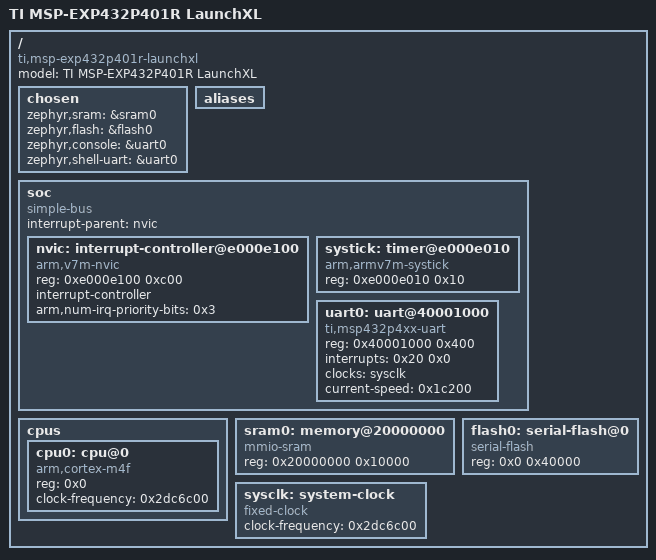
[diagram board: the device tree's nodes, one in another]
/dts-v1/;

/* node '/' defined in zephyr/dts/common/skeleton.dtsi:9 */
/ {
	#address-cells = < 0x1 >;                   /* in zephyr/dts/common/skeleton.dtsi:10 */
	#size-cells = < 0x1 >;                      /* in zephyr/dts/common/skeleton.dtsi:11 */
	model = "TI MSP-EXP432P401R LaunchXL";      /* in zephyr/boards/ti/msp_exp432p401r_launchxl/msp_exp432p401r_launchxl.dts:9 */
	compatible = "ti,msp-exp432p401r-launchxl",
	             "ti,msp432p401r",
	             "ti,msp432p4xx";               /* in zephyr/boards/ti/msp_exp432p401r_launchxl/msp_exp432p401r_launchxl.dts:10 */

	/* node '/chosen' defined in zephyr/dts/common/skeleton.dtsi:13 */
	chosen {
		zephyr,sram = &sram0;       /* in zephyr/boards/ti/msp_exp432p401r_launchxl/msp_exp432p401r_launchxl.dts:14 */
		zephyr,flash = &flash0;     /* in zephyr/boards/ti/msp_exp432p401r_launchxl/msp_exp432p401r_launchxl.dts:15 */
		zephyr,console = &uart0;    /* in zephyr/boards/ti/msp_exp432p401r_launchxl/msp_exp432p401r_launchxl.dts:16 */
		zephyr,shell-uart = &uart0; /* in zephyr/boards/ti/msp_exp432p401r_launchxl/msp_exp432p401r_launchxl.dts:17 */
	};

	/* node '/aliases' defined in zephyr/dts/common/skeleton.dtsi:15 */
	aliases {
	};

	/* node '/soc' defined in zephyr/dts/arm/armv7-m.dtsi:6 */
	soc {
		#address-cells = < 0x1 >;     /* in zephyr/dts/arm/armv7-m.dtsi:7 */
		#size-cells = < 0x1 >;        /* in zephyr/dts/arm/armv7-m.dtsi:8 */
		compatible = "simple-bus";    /* in zephyr/dts/arm/armv7-m.dtsi:9 */
		interrupt-parent = < &nvic >; /* in zephyr/dts/arm/armv7-m.dtsi:10 */
		ranges;                       /* in zephyr/dts/arm/armv7-m.dtsi:11 */

		/* node '/soc/interrupt-controller@e000e100' defined in zephyr/dts/arm/armv7-m.dtsi:13 */
		nvic: interrupt-controller@e000e100 {
			#address-cells = < 0x1 >;            /* in zephyr/dts/arm/armv7-m.dtsi:14 */
			compatible = "arm,v7m-nvic";         /* in zephyr/dts/arm/armv7-m.dtsi:15 */
			reg = < 0xe000e100 0xc00 >;          /* in zephyr/dts/arm/armv7-m.dtsi:16 */
			interrupt-controller;                /* in zephyr/dts/arm/armv7-m.dtsi:17 */
			#interrupt-cells = < 0x2 >;          /* in zephyr/dts/arm/armv7-m.dtsi:18 */
			arm,num-irq-priority-bits = < 0x3 >; /* in zephyr/dts/arm/ti/msp432p4xx.dtsi:42 */
			phandle = < 0x1 >;                   /* in zephyr/dts/arm/armv7-m.dtsi:10 */
		};

		/* node '/soc/timer@e000e010' defined in zephyr/dts/arm/armv7-m.dtsi:21 */
		systick: timer@e000e010 {
			compatible = "arm,armv7m-systick"; /* in zephyr/dts/arm/armv7-m.dtsi:22 */
			reg = < 0xe000e010 0x10 >;         /* in zephyr/dts/arm/armv7-m.dtsi:23 */
		};

		/* node '/soc/uart@40001000' defined in zephyr/dts/arm/ti/msp432p4xx.dtsi:31 */
		uart0: uart@40001000 {
			compatible = "ti,msp432p4xx-uart"; /* in zephyr/dts/arm/ti/msp432p4xx.dtsi:32 */
			reg = < 0x40001000 0x400 >;        /* in zephyr/dts/arm/ti/msp432p4xx.dtsi:33 */
			interrupts = < 0x20 0x0 >;         /* in zephyr/dts/arm/ti/msp432p4xx.dtsi:34 */
			clocks = < &sysclk >;              /* in zephyr/dts/arm/ti/msp432p4xx.dtsi:35 */
			status = "okay";                   /* in zephyr/boards/ti/msp_exp432p401r_launchxl/msp_exp432p401r_launchxl.dts:26 */
			current-speed = < 0x1c200 >;       /* in zephyr/boards/ti/msp_exp432p401r_launchxl/msp_exp432p401r_launchxl.dts:27 */
		};
	};

	/* node '/cpus' defined in zephyr/dts/arm/ti/msp432p4xx.dtsi:6 */
	cpus {
		#address-cells = < 0x1 >; /* in zephyr/dts/arm/ti/msp432p4xx.dtsi:7 */
		#size-cells = < 0x0 >;    /* in zephyr/dts/arm/ti/msp432p4xx.dtsi:8 */

		/* node '/cpus/cpu@0' defined in zephyr/dts/arm/ti/msp432p4xx.dtsi:10 */
		cpu0: cpu@0 {
			compatible = "arm,cortex-m4f";   /* in zephyr/dts/arm/ti/msp432p4xx.dtsi:11 */
			reg = < 0x0 >;                   /* in zephyr/dts/arm/ti/msp432p4xx.dtsi:12 */
			clock-frequency = < 0x2dc6c00 >; /* in zephyr/boards/ti/msp_exp432p401r_launchxl/msp_exp432p401r_launchxl.dts:22 */
		};
	};

	/* node '/memory@20000000' defined in zephyr/dts/arm/ti/msp432p4xx.dtsi:16 */
	sram0: memory@20000000 {
		compatible = "mmio-sram";     /* in zephyr/dts/arm/ti/msp432p4xx.dtsi:17 */
		reg = < 0x20000000 0x10000 >; /* in zephyr/dts/arm/ti/msp432p401r.dtsi:12 */
	};

	/* node '/serial-flash@0' defined in zephyr/dts/arm/ti/msp432p4xx.dtsi:20 */
	flash0: serial-flash@0 {
		compatible = "serial-flash"; /* in zephyr/dts/arm/ti/msp432p4xx.dtsi:21 */
		reg = < 0x0 0x40000 >;       /* in zephyr/dts/arm/ti/msp432p401r.dtsi:16 */
	};

	/* node '/system-clock' defined in zephyr/dts/arm/ti/msp432p4xx.dtsi:24 */
	sysclk: system-clock {
		compatible = "fixed-clock";      /* in zephyr/dts/arm/ti/msp432p4xx.dtsi:25 */
		clock-frequency = < 0x2dc6c00 >; /* in zephyr/dts/arm/ti/msp432p4xx.dtsi:26 */
		#clock-cells = < 0x0 >;          /* in zephyr/dts/arm/ti/msp432p4xx.dtsi:27 */
		phandle = < 0x2 >;               /* in zephyr/dts/arm/ti/msp432p4xx.dtsi:35 */
	};
};
